# nrf7120E_enga_application register map
Vendor: Nordic Semiconductor; Series: nrf71; File version: 1
CPU: CM33 r0p4, little endian, MPU, FPU, 3 interrupt priority bits, 270 interrupts, 4 SAU regions
Registers are 32-bit, read-write, reset 0x0 unless marked. A register's access mark holds for its fields unless they carry their own. Offsets are from the block's base; [hi:lo] are bit positions; lines under a group give offsets from that group; {n}, {i} and the like mark numbered series; 'fields as' and 'values as' point back to an identical list.

## GLOBAL_USBHSCORE_NS (part 2 of 2) — USBHSCORE 0
Base 0x40020000
Same registers: GLOBAL_USBHSCORE_S 0x50020000
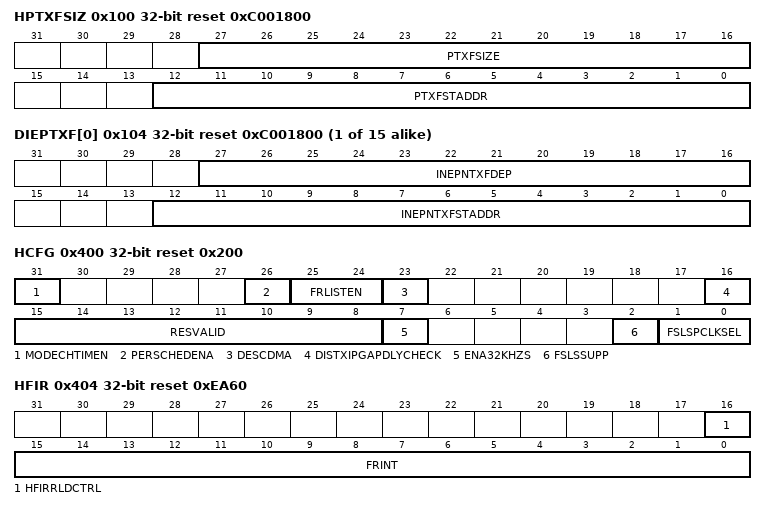
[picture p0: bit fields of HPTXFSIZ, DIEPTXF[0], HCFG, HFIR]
0x100 HPTXFSIZ reset 0xC001800 — Host Periodic Transmit FIFO Size Register
  [27:16] PTXFSIZE — Host Periodic TxFIFO Depth (PTxFSize)
  [12:0] PTXFSTADDR — Host Periodic TxFIFO Start Address (PTxFStAddr)
{0x104+4i} DIEPTXF[{i}] (i=0..14) reset 0xC001800 — Description collection: Device IN Endpoint Transmit FIFO 1 Size Register
  [27:16] INEPNTXFDEP — IN Endpoint TxFIFO Depth (INEPnTxFDep)
  [12:0] INEPNTXFSTADDR — IN Endpoint FIFOn Transmit RAM Start Address (INEPnTxFStAddr)
0x400 HCFG reset 0x200 — Host Configuration Register
  [31] MODECHTIMEN — Mode Change Ready Timer Enable (ModeChTimEn)
    0=ENABLED (The Host core waits for either 200 PHY clock cycles or a linestate of SE0 at the end of resume to change the opmode from 0x2 to 0x0); 1=DISABLED (The Host core waits only for a linestate of SE0 at the end of resume to change the opmode from 0x2 to 0x0)
  [26] PERSCHEDENA — Enable Periodic Scheduling (PerSchedEna):
    0=DISABLED (Disables periodic scheduling within the core); 1=ENABLED (Enables periodic scheduling within the core)
  [25:24] FRLISTEN — Frame List Entries(FrListEn)
    0=ENTRY8 (8 Entries); 1=ENTRY16 (16 Entries); 2=ENTRY32 (32 Entries); 3=ENTRY63 (64 Entries)
  [23] DESCDMA — Enable Scatter/gather DMA in Host mode (DescDMA)
    0=DISABLED (Scatter/Gather DMA in Host mode is disabled); 1=ENABLED (Scatter/Gather DMA selected)
  [16] DISTXIPGAPDLYCHECK — Disable Linestate check for Token to Token/Data interpacket gap delay calculation (dis_tx_ipgap_dly_check)
    0=DISABLE (Enable Linestate check); 1=ENABLE (Disable Linestate check)
  [15:8] RESVALID — Resume Validation Period (ResValid)
  [7] ENA32KHZS — Enable 32 KHz Suspend mode (Ena32KHzS)
    0=DISABLED (32 KHz Suspend mode disabled); 1=ENABLED (32 KHz Suspend mode enabled)
  [2] FSLSSUPP — FS- and LS-Only Support (FSLSSupp)
    0=HSFSLS (HS/FS/LS, based on the maximum speed supported by the connected device); 1=FSLS (FS/LS-only, even if the connected device can support HS)
  [1:0] FSLSPCLKSEL — FS/LS PHY Clock Select (FSLSPclkSel)
    0=CLK3060 (PHY clock is running at 30/60 MHz); 1=CLK48 (PHY clock is running at 48 MHz); 2=CLK6 (PHY clock is running at 6 MHz)
0x404 HFIR reset 0xEA60 — Host Frame Interval Register
  [16] HFIRRLDCTRL — Reload Control (HFIRRldCtrl)
    0=DISABLED (The HFIR cannot be reloaded dynamically); 1=ENABLED (The HFIR can be dynamically reloaded during runtime)
  [15:0] FRINT — Frame Interval (FrInt)
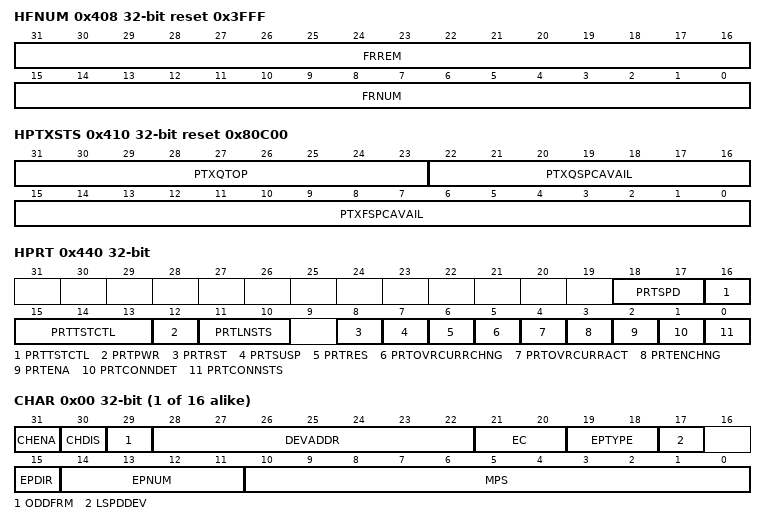
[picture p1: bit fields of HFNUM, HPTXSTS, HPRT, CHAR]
0x408 HFNUM reset 0x3FFF — Host Frame Number/Frame Time Remaining Register
  [31:16] FRREM ro — Frame Time Remaining (FrRem)
  [15:0] FRNUM ro — Frame Number (FrNum)
    0=INACTIVE (No SOF is transmitted); 1=ACTIVE (SOF is transmitted)
0x410 HPTXSTS reset 0x80C00 — Host Periodic Transmit FIFO/Queue Status Register
  [31:23] PTXQTOP ro — Top of the Periodic Transmit Request Queue (PTxQTop)
  [22:16] PTXQSPCAVAIL ro — Periodic Transmit Request Queue Space Available (PTxQSpcAvail)
    0=FULL (Periodic Transmit Request Queue is full); 1=FREE1 (1 location available); {v}=FREE{v} ({v} locations available) (v=2..15)
  [15:0] PTXFSPCAVAIL ro — Periodic Transmit Data FIFO Space Available (PTxFSpcAvail)
0x414 HAINT — Host All Channels Interrupt Register
  [15:0] HAINT ro
    0=INACTIVE (Not active); 1=ACTIVE (Host Channel Interrupt)
0x418 HAINTMSK — Host All Channels Interrupt Mask Register
  [15:0] HAINTMSK — Channel Interrupt Mask (HAINTMsk)
    0=MASK (Mask Channel interrupt); 1=UNMASK (UnMask Channel interrupt)
0x41C HFLBADDR — Host Frame List Base Address Register
  [31:0] HFLBADDR — The starting address of the Frame list.
0x440 HPRT — Host Port Control and Status Register
  [18:17] PRTSPD ro — Port Speed (PrtSpd)
    0=HIGHSPD (High speed); 1=FULLSPD (Full speed); 2=LOWSPD (Low speed)
  [16:13] PRTTSTCTL — Port Test Control (PrtTstCtl)
    0=DISABLED (Test mode disabled); 1=TESTJ (Test_J mode); 2=TESTK (Test_K mode); 3=TESTSN (Test_SE0_NAK mode); 4=TESTPM (Test_Packet mode); 5=TESTFENB (Test_force_Enable)
  [12] PRTPWR — Port Power (PrtPwr)
    0=OFF (Power off); 1=ON (Power on)
  [11:10] PRTLNSTS ro — Port Line Status (PrtLnSts)
    1=PLUSD (Logic level of D+); 2=MINUSD (Logic level of D-)
  [8] PRTRST — Port Reset (PrtRst)
    0=DISABLED (Port not in reset); 1=ENABLED (Port in reset)
  [7] PRTSUSP — Port Suspend (PrtSusp)
    0=INACTIVE (Port not in Suspend mode); 1=ACTIVE (Port in Suspend mode)
  [6] PRTRES — Port Resume (PrtRes)
    0=NORESUME (No resume driven); 1=RESUME (Resume driven)
  [5] PRTOVRCURRCHNG — Port Overcurrent Change (PrtOvrCurrChng)
    0=INACTIVE (Status of port overcurrent status is not changed); 1=ACTIVE (Status of port overcurrent changed)
  [4] PRTOVRCURRACT ro — Port Overcurrent Active (PrtOvrCurrAct)
    0=INACTIVE (No overcurrent condition); 1=ACTIVE (Overcurrent condition)
  [3] PRTENCHNG — Port Enable/Disable Change (PrtEnChng)
    0=INACTIVE (Port Enable bit 2 has not changed); 1=ACTIVE (Port Enable bit 2 changed)
  [2] PRTENA — Port Enable (PrtEna)
    0=DISABLED (Port disabled); 1=ENABLED (Port enabled)
  [1] PRTCONNDET — Port Connect Detected (PrtConnDet)
    0=INACTIVE (No device connection detected); 1=ACTIVE (Device connection detected)
  [0] PRTCONNSTS ro — Port Connect Status (PrtConnSts)
    0=NOTATTACHED (No device is attached to the port); 1=ATTACHED (A device is attached to the port)
{0x500+0x20*i} HC[{i}] (i=0..15) group — Unspecified
  0x00 CHAR — Description cluster: Host Channel Characteristics Register 0
    [31] CHENA — Channel Enable (ChEna)
      0=DISABLED (If Scatter/Gather mode is enabled, indicates that the descriptor structure is not yet ready. If Scatter/Gather mode is disabled, indicates that the channel is disabled.); 1=ENABLED (If Scatter/Gather mode is enabled, indicates that the descriptor structure and data buffer with data is set up and this channel can access the descriptor. If Scatter/Gather mode is disabled, indicates that the channel is enabled.)
    [30] CHDIS — Channel Disable (ChDis)
      0=INACTIVE (Transmit/Recieve normal); 1=ACTIVE (Stop transmitting/receiving data on channel)
    [29] ODDFRM — Odd Frame (OddFrm)
      0=EFRAME (Even Frame Transfer); 1=OFRAME (Odd Frame Transfer)
    [28:22] DEVADDR — Device Address (DevAddr)
    [21:20] EC — Multi Count (MC) / Error Count (EC)
      1=TRANSONE (1 transaction); 2=TRANSTWO (2 transactions to be issued for this endpoint per microframe); 3=TRANSTHREE (3 transactions to be issued for this endpoint per microframe)
    [19:18] EPTYPE — Endpoint Type (EPType)
      0=CTRL (Control); 1=ISOC (Isochronous); 2=BULK; 3=INTERR (Interrupt)
    [17] LSPDDEV — Low-Speed Device (LSpdDev)
      0=DISABLED (Not Communicating with low speed device); 1=ENABLED (Communicating with low speed device)
    [15] EPDIR — Endpoint Direction (EPDir)
      0=OUT (OUT Direction); 1=IN (IN Direction)
    [14:11] EPNUM — Endpoint Number (EPNum)
      {v}=ENDPT{v} (End point {v}) (v=0..15)
    [10:0] MPS — Maximum Packet Size (MPS)
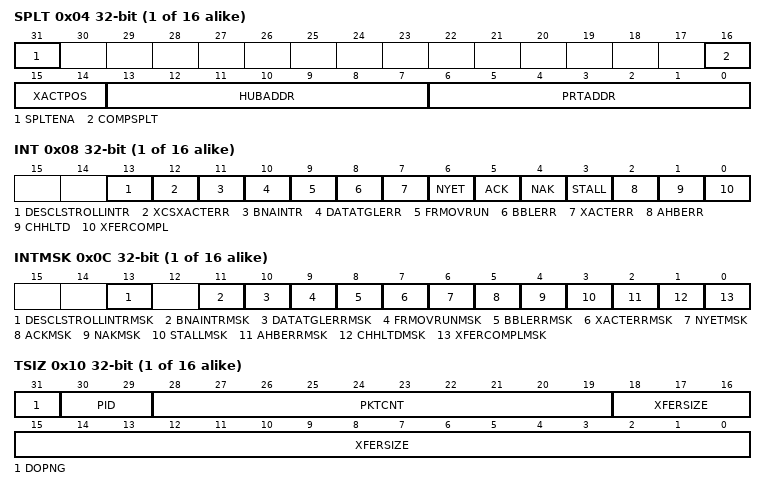
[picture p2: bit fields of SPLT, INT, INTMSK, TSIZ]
  0x04 SPLT — Description cluster: Host Channel Split Control Register 0
    [31] SPLTENA — Split Enable (SpltEna)
      0=DISABLED (Split not enabled); 1=ENABLED (Split enabled)
    [16] COMPSPLT — Do Complete Split (CompSplt)
      0=NOSPLIT (No complete split transaction); 1=SPLIT (Complete Split transaction)
    [15:14] XACTPOS — Transaction Position (XactPos)
      0=MIDDLE (Mid. This is the middle payload of this transaction (which is larger than 188 bytes)); 1=END (End. This is the last payload of this transaction (which is larger than 188 bytes)); 2=BEGIN (Begin. This is the first data payload of this transaction (which is larger than 188 bytes)); 3=ALL (All. This is the entire data payload of this transaction (which is less than or equal to 188 bytes))
    [13:7] HUBADDR — Hub Address (HubAddr)
    [6:0] PRTADDR — Port Address (PrtAddr)
  0x08 INT — Description cluster: Host Channel Interrupt Register 0
    [13] DESCLSTROLLINTR — Descriptor rollover interrupt (DESC_LST_ROLLIntr)
      0=INACTIVE (No Descriptor rollover interrupt); 1=ACTIVE (Descriptor rollover interrupt)
    [12] XCSXACTERR — Excessive Transaction Error (XCS_XACT_ERR)
      0=INACTIVE (No Excessive Transaction Error); 1=ACTIVE (Excessive Transaction Error)
    [11] BNAINTR — BNA (Buffer Not Available) Interrupt (BNAIntr)
      0=INACTIVE (No BNA Interrupt); 1=ACTIVE (BNA Interrupt)
    [10] DATATGLERR
      0=INACTIVE (No Data Toggle Error); 1=ACTIVE (Data Toggle Error)
    [9] FRMOVRUN — Frame Overrun (FrmOvrun).
      0=INACTIVE (No Frame Overrun); 1=ACTIVE (Frame Overrun)
    [8] BBLERR — Babble Error (BblErr)
      0=INACTIVE (No Babble Error); 1=ACTIVE (Babble Error)
    [7] XACTERR — Transaction Error (XactErr)
      0=INACTIVE (No Transaction Error); 1=ACTIVE (Transaction Error)
    [6] NYET — NYET Response Received Interrupt (NYET)
      0=INACTIVE (No NYET Response Received Interrupt); 1=ACTIVE (NYET Response Received Interrupt)
    [5] ACK — ACK Response Received/Transmitted Interrupt (ACK)
      0=INACTIVE (No ACK Response Received or Transmitted Interrupt); 1=ACTIVE (ACK Response Received or Transmitted Interrup)
    [4] NAK — NAK Response Received Interrupt (NAK)
      0=INACTIVE (No NAK Response Received Interrupt); 1=ACTIVE (NAK Response Received Interrupt)
    [3] STALL — STALL Response Received Interrupt (STALL)
      0=INACTIVE (No Stall Response Received Interrupt); 1=ACTIVE (Stall Response Received Interrupt)
    [2] AHBERR — AHB Error (AHBErr)
      0=INACTIVE (No AHB error); 1=ACTIVE (AHB error during AHB read/write)
    [1] CHHLTD — Channel Halted (ChHltd)
      0=INACTIVE (Channel not halted); 1=ACTIVE (Channel Halted)
    [0] XFERCOMPL — Transfer Completed (XferCompl)
      0=INACTIVE (Transfer in progress or No Active Transfer); 1=ACTIVE (Transfer completed normally without any errors)
  0x0C INTMSK — Description cluster: Host Channel Interrupt Mask Register 0
    [13] DESCLSTROLLINTRMSK
      0=MASK (Descriptor Rollover Interrupt Mask); 1=NOMASK (Descriptor Rollover Interrupt not masked)
    [11] BNAINTRMSK
      0=MASK (BNA Interrupt Masked); 1=NOMASK (BNA Interrupt not masked)
    [10] DATATGLERRMSK
      0=MASK (Mask Data Toggle Error); 1=NOMASK (No Data Toggle Error Mask)
    [9] FRMOVRUNMSK
      0=MASK (Mask Overrun Mask); 1=NOMASK (No Frame Overrun Mask)
    [8] BBLERRMSK
      0=MASK (Mask Babble Error); 1=NOMASK (No Babble Error Mask)
    [7] XACTERRMSK
      0=MASK (Mask Transaction Error); 1=NOMASK (No Transaction Error Mask)
    [6] NYETMSK
      0=MASK (Mask NYET Response Received Interrupt); 1=NOMASK (No NYET Response Received Interrupt Mask)
    [5] ACKMSK
      0=MASK (Mask ACK Response Received/Transmitted Interrupt); 1=NOMASK (No ACK Response Received/Transmitted Interrupt Mask)
    [4] NAKMSK
      0=MASK (Mask NAK Response Received Interrupt); 1=NOMASK (No NAK Response Received Interrupt Mask)
    [3] STALLMSK
      0=MASK (Mask STALL Response Received Interrupt); 1=NOMASK (No STALL Response Received Interrupt Mask)
    [2] AHBERRMSK
      0=MASK (AHB Error Mask); 1=NOMASK (No AHB Error Mask)
    [1] CHHLTDMSK
      0=MASK (Channel Halted Mask); 1=NOMASK (No Channel Halted Mask)
    [0] XFERCOMPLMSK
      0=MASK (Transfer Completed Mask); 1=NOMASK (No Transfer Completed Mask)
  0x10 TSIZ — Description cluster: Host Channel Transfer Size Register 0
    [31] DOPNG — Do Ping (DoPng)
      0=NOPING (No ping protocol); 1=PING (Ping protocol)
    [30:29] PID — PID (Pid)
      0=DATA0; 1=DATA2; 2=DATA1; 3=MDATA (MDATA (non-control)/SETUP (control))
    [28:19] PKTCNT — Non-Scatter/Gather DMA Mode:
    [18:0] XFERSIZE — Non-Scatter/Gather DMA Mode:
  0x14 DMA — Description cluster: Host Channel DMA Address Register 0
    [31:0] DMAADDR — In Buffer DMA Mode:
  0x1C DMAB — Description cluster: Host Channel DMA Buffer Address Register 0
    [31:0] HCDMAB ro — Holds the current buffer address.
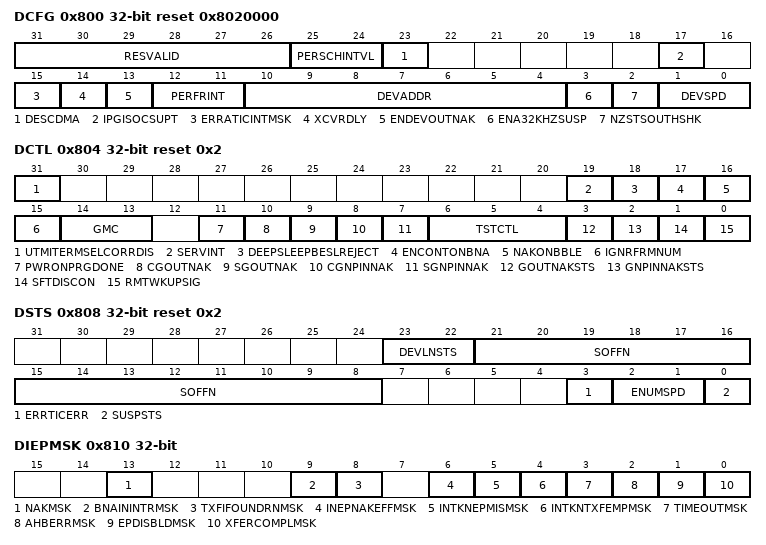
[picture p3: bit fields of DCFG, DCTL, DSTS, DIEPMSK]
0x800 DCFG reset 0x8020000 — Device Configuration Register
  [31:26] RESVALID — Resume Validation Period (ResValid)
  [25:24] PERSCHINTVL — Periodic Scheduling Interval (PerSchIntvl)
    0=MF25 (25 percent of (micro)Frame); 1=MF50 (50 percent of (micro)Frame); 2=MF75 (75 percent of (micro)Frame)
  [23] DESCDMA — Enable Scatter/gather DMA in device mode (DescDMA).
    0=DISABLED (Disable Scatter/Gather DMA); 1=ENABLED (Enable Scatter/Gather DMA)
  [17] IPGISOCSUPT — Worst-Case Inter-Packet Gap ISOC OUT Support (ipgisocSupt)
    0=DISABLED (Worst-Case Inter-Packet Gap ISOC OUT Support is disabled); 1=ENABLED (Worst-Case Inter-Packet Gap ISOC OUT Support is enabled)
  [15] ERRATICINTMSK — Erratic Error Interrupt Mask
    0=NOMASK (Early suspend interrupt is generated on erratic error); 1=MASK (Mask early suspend interrupt on erratic error)
  [14] XCVRDLY
    0=DISABLE (No delay between xcvr_sel and txvalid during Device chirp); 1=ENABLE (Enable delay between xcvr_sel and txvalid during Device chirp)
  [13] ENDEVOUTNAK — Enable Device OUT NAK (EnDevOutNak)
    0=DISABLED (The core does not set NAK after Bulk OUT transfer complete); 1=ENABLED (The core sets NAK after Bulk OUT transfer complete)
  [12:11] PERFRINT — Periodic Frame Interval (PerFrInt)
    0=EOPF80 (80 percent of the (micro)Frame interval); 1=EOPF85 (85 percent of the (micro)Frame interval); 2=EOPF90 (90 percent of the (micro)Frame interval); 3=EOPF95 (95 percent of the (micro)Frame interval)
  [10:4] DEVADDR — Device Address (DevAddr)
  [3] ENA32KHZSUSP — Enable 32 KHz Suspend mode (Ena32KHzSusp)
    0=DISABLED (USB 1.1 Full-Speed Serial Transceiver not selected); 1=ENABLED (USB 1.1 Full-Speed Serial Transceiver Interface selected)
  [2] NZSTSOUTHSHK — Non-Zero-Length Status OUT Handshake (NZStsOUTHShk)
    0=SENDOUT (Send the received OUT packet to the application (zero-length or non-zero length) and send a handshake based on NAK and STALL bits for the endpoint in the Devce Endpoint Control Register); 1=SENDSTALL (Send a STALL handshake on a nonzero-length status OUT transaction and do not send the received OUT packet to the application)
  [1:0] DEVSPD — Device Speed (DevSpd)
    0=USBHS20 (High speed USB 2.0 PHY clock is 30 MHz or 60 MHz); 1=USBFS20 (Full speed USB 2.0 PHY clock is 30 MHz or 60 MHz); 2=USBLS116 (Low speed USB 1.1 transceiver clock is 6 MHz); 3=USBFS1148 (Full speed USB 1.1 transceiver clock is 48 MHz)
0x804 DCTL reset 0x2 — Device Control Register
  [31] UTMITERMSELCORRDIS — Disable the correction of TermSel on UTMI Interface.
    0=DISABLED (Valid Combination of XcvrSel and TermSel is driven by the Device Controller.); 1=ENABLED (Invalid Combination of XcvrSel and TermSel is driven by the Device Controller.)
  [19] SERVINT — Service Interval based scheduling for Isochronous IN Endpoints
    0=DISABLED (The controller behavior depends on DCTL.IgnrFrmNum field.); 1=ENABLED (Scatter/Gather DMA Mode: The controller can transmit the packets in any frame of the service interval.)
  [18] DEEPSLEEPBESLREJECT
    0=DISABLED (Deep Sleep BESL Reject feature is disabled); 1=ENABLED (Deep Sleep BESL Reject feature is enabled)
  [17] ENCONTONBNA — Enable Continue on BNA (EnContOnBNA)
    0=DISABLED (Core disables the endpoint after receiving BNA interrupt. When application re-enables the endpoint, core starts processing from the DOEPDMA descriptor); 1=ENABLED (Core disables the endpoint after receiving BNA interrupt. When application re-enables the endpoint, core starts processing from the descriptor that received the BNA interrupt.)
  [16] NAKONBBLE — NAK on Babble Error (NakOnBble)
    0=DISABLED (Disable NAK on Babble Error); 1=ENABLED (NAK on Babble Error)
  [15] IGNRFRMNUM — Ignore Frame Number Feature for Isochronous Endpoints (IgnrFrmNum)
    0=DISABLED (Scatter/Gather DMA Mode: The core transmits the packets only in the frame number in which they are intended to be transmitted.Non-Scatter/Gather DMA Mode: Periodic Transfer Interrupt feature is disabled.); 1=ENABLED (Scatter/Gather DMA Mode: The core ignores the frame number, sending packets immediately as the packets are ready.Non-Scatter/Gather DMA Mode: Periodic Transfer Interrupt feature is enabled.)
  [14:13] GMC — Global Multi Count (GMC)
    0=NOTVALID (Invalid); 1=ONEPACKET (1 packet); 2=TWOPACKET (2 packets); 3=THREEPACKET (3 packets)
  [11] PWRONPRGDONE — Power-On Programming Done (PWROnPrgDone)
    0=NOTDONE (Power-On Programming not done); 1=DONE (Power-On Programming Done)
  [10] CGOUTNAK wo — Clear Global OUT NAK (CGOUTNak)
    0=DISABLED (Disable Clear Global OUT NAK); 1=ENABLED (Clear Global OUT NAK)
  [9] SGOUTNAK wo — Set Global OUT NAK (SGOUTNak)
    0=DISABLED (Disable Global OUT NAK); 1=ENABLED (Set Global OUT NAK)
  [8] CGNPINNAK wo — Clear Global Non-periodic IN NAK (CGNPInNak)
    0=DISABLE (Disable Global Non-periodic IN NAK); 1=ENABLE (Clear Global Non-periodic IN NAK)
  [7] SGNPINNAK wo — Set Global Non-periodic IN NAK (SGNPInNak)
    0=DISABLE (Disable Global Non-periodic IN NAK); 1=ENABLE (Set Global Non-periodic IN NAK)
  [6:4] TSTCTL — Test Control (TstCtl)
    0=DISABLED (Test mode disabled); 1=TESTJ (Test_J mode); 2=TESTK (Test_K mode); 3=TESTSN (Test_SE0_NAK mode); 4=TESTPM (Test_Packet mode); 5=TESTFE (Test_force_Enable)
  [3] GOUTNAKSTS ro — Global OUT NAK Status (GOUTNakSts)
    0=INACTIVE (A handshake is sent based on the FIFO Status and the NAK and STALL bit settings.); 1=ACTIVE (No data is written to the RxFIFO, irrespective of space availability. Sends a NAK handshake on all packets, except on SETUP transactions. All isochronous OUT packets are dropped.)
  [2] GNPINNAKSTS ro — Global Non-periodic IN NAK Status (GNPINNakSts)
    0=INACTIVE (A handshake is sent out based on the data availability in the transmit FIFO); 1=ACTIVE (A NAK handshake is sent out on all non-periodic IN endpoints, irrespective of the data availability in the transmit FIFO.)
  [1] SFTDISCON — Soft Disconnect (SftDiscon)
    0=NODISCONNECT (The core drives the phy_opmode_o signal on the UTMI+ to 2'b00, which generates a device connect event to the USB host); 1=DISCONNECT (The core drives the phy_opmode_o signal on the UTMI+ to 2'b01, which generates a device disconnect event to the USB host)
  [0] RMTWKUPSIG — Remote Wakeup Signaling (RmtWkUpSig)
    0=DISABLEDRMWKUP (Core does not send Remote Wakeup Signaling); 1=ENABLERMWKUP (Core sends Remote Wakeup Signaling)
0x808 DSTS reset 0x2 — Device Status Register
  [23:22] DEVLNSTS ro — Device Line Status (DevLnSts)
  [21:8] SOFFN ro — Frame or Microframe Number of the Received SOF (SOFFN)
  [3] ERRTICERR ro — Erratic Error (ErrticErr)
    0=INACTIVE (No Erratic Error); 1=ACTIVE (Erratic Error)
  [2:1] ENUMSPD ro — Enumerated Speed (EnumSpd)
    0=HS3060 (High speed (PHY clock is running at 30 or 60 MHz)); 1=FS3060 (Full speed (PHY clock is running at 30 or 60 MHz)); 2=LS6 (Low speed (PHY clock is running at 6 MHz)); 3=FS48 (Full speed (PHY clock is running at 48 MHz))
  [0] SUSPSTS ro — Suspend Status (SuspSts)
    0=INACTIVE (No suspend state); 1=ACTIVE (Suspend state)
0x810 DIEPMSK — Device IN Endpoint Common Interrupt Mask Register
  [13] NAKMSK — NAK interrupt Mask (NAKMsk)
    0=MASK (Mask NAK Interrupt); 1=NOMASK (No Mask NAK Interrupt)
  [9] BNAININTRMSK — BNA interrupt Mask (BNAInIntrMsk)
    0=MASK (Mask BNA Interrupt); 1=NOMASK (No BNA Interrupt Mask)
  [8] TXFIFOUNDRNMSK — Fifo Underrun Mask (TxfifoUndrnMsk)
    0=MASK (Mask Fifo Underrun Interrupt); 1=NOMASK (No Fifo Underrun Interrupt Mask)
  [6] INEPNAKEFFMSK — IN Endpoint NAK Effective Mask (INEPNakEffMsk)
    0=MASK (Mask IN Endpoint NAK Effective Interrupt); 1=NOMASK (No IN Endpoint NAK Effective Interrupt Mask)
  [5] INTKNEPMISMSK — IN Token received with EP Mismatch Mask (INTknEPMisMsk)
    0=MASK (Mask IN Token received with EP Mismatch Interrupt); 1=NOMASK (No Mask IN Token received with EP Mismatch Interrupt)
  [4] INTKNTXFEMPMSK — IN Token Received When TxFIFO Empty Mask (INTknTXFEmpMsk)
    0=MASK (Mask IN Token Received When TxFIFO Empty Interrupt); 1=NOMASK (No IN Token Received When TxFIFO Empty Interrupt)
  [3] TIMEOUTMSK — Timeout Condition Mask (TimeOUTMsk) (Non-isochronous endpoints)
    0=MASK (Mask Timeout Condition Interrupt); 1=NOMASK (No Timeout Condition Interrupt Mask)
  [2] AHBERRMSK — AHB Error Mask (AHBErrMsk)
    0=MASK (Mask AHB Error Interrupt); 1=NOMASK (No AHB Error Interrupt Mask)
  [1] EPDISBLDMSK — Endpoint Disabled Interrupt Mask (EPDisbldMsk)
    0=MASK (Mask Endpoint Disabled Interrupt); 1=NOMASK (No Endpoint Disabled Interrupt Mask)
  [0] XFERCOMPLMSK — Transfer Completed Interrupt Mask (XferComplMsk)
    0=MASK (Mask Transfer Completed Interrupt); 1=NOMASK (No Transfer Completed Interrupt Mask)
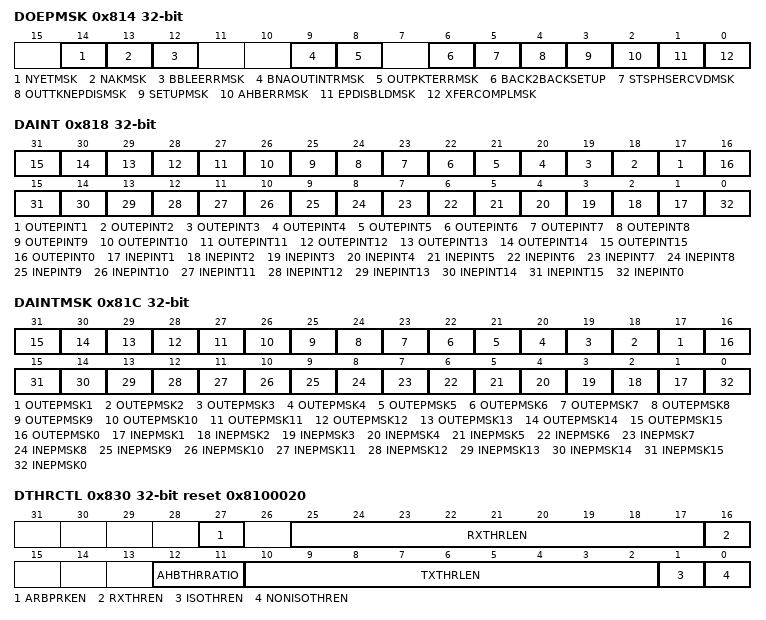
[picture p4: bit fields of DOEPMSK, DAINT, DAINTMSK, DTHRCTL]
0x814 DOEPMSK — Device OUT Endpoint Common Interrupt Mask Register
  [14] NYETMSK — NYET interrupt Mask (NYETMsk)
    0=MASK (Mask NYET Interrupt); 1=NOMASK (No NYET Interrupt Mask)
  [13] NAKMSK — NAK interrupt Mask (NAKMsk)
    0=MASK (Mask NAK Interrupt); 1=NOMASK (No NAK Interrupt Mask)
  [12] BBLEERRMSK — Babble Error interrupt Mask (BbleErrMsk)
    0=MASK (Mask Babble Error Interrupt); 1=NOMASK (No Babble Error Interrupt Mask)
  [9] BNAOUTINTRMSK — BNA interrupt Mask (BnaOutIntrMsk)
    values as DIEPMSK.BNAININTRMSK
  [8] OUTPKTERRMSK — OUT Packet Error Mask (OutPktErrMsk)
    0=MASK (Mask OUT Packet Error Interrupt); 1=NOMASK (No OUT Packet Error Interrupt Mask)
  [6] BACK2BACKSETUP — Back-to-Back SETUP Packets Received Mask (Back2BackSETup)
    0=MASK (Mask Back-to-Back SETUP Packets Received Interrupt); 1=NOMASK (No Back-to-Back SETUP Packets Received Interrupt Mask)
  [5] STSPHSERCVDMSK — Status Phase Received Mask (StsPhseRcvdMsk)
    0=MASK (Status Phase Received Mask); 1=NOMASK (No Status Phase Received Mask)
  [4] OUTTKNEPDISMSK — OUT Token Received when Endpoint Disabled Mask (OUTTknEPdisMsk)
    0=MASK (Mask OUT Token Received when Endpoint Disabled Interrupt); 1=NOMASK (No OUT Token Received when Endpoint Disabled Interrupt Mask)
  [3] SETUPMSK — SETUP Phase Done Mask (SetUPMsk)
    0=MASK (Mask SETUP Phase Done Interrupt); 1=NOMASK (No SETUP Phase Done Interrupt Mask)
  [2] AHBERRMSK — AHB Error (AHBErrMsk)
    values as DIEPMSK.AHBERRMSK
  [1] EPDISBLDMSK — Endpoint Disabled Interrupt Mask (EPDisbldMsk)
    values as DIEPMSK.EPDISBLDMSK
  [0] XFERCOMPLMSK — Transfer Completed Interrupt Mask (XferComplMsk)
    values as DIEPMSK.XFERCOMPLMSK
0x818 DAINT — Device All Endpoints Interrupt Register
  [n+16] OUTEPINT{n} ro (n=1..15) — OUT Endpoint {n} Interrupt Bit
    0=INACTIVE (No Interrupt); 1=ACTIVE (Interrupt is active for the OUT EP)
  [16] OUTEPINT0 ro — OUT Endpoint 0 Interrupt Bit
    0=INACTIVE (No Interrupt); 1=ACTIVE (Interrupt is active for OUT EP0)
  [n] INEPINT{n} ro (n=1..15) — IN Endpoint {n} Interrupt Bit
    0=INACTIVE (No Interrupt); 1=ACTIVE (Interrupt is active for the IN EP)
  [0] INEPINT0 ro — IN Endpoint 0 Interrupt Bit
    0=INACTIVE (No Interrupt); 1=ACTIVE (Interrupt is active for IN EP0)
0x81C DAINTMSK — Device All Endpoints Interrupt Mask Register
  [n+16] OUTEPMSK{n} (n=1..15) — OUT Endpoint {n} Interrupt mask Bit
    0=MASK (Mask OUT Endpoint Interrupt); 1=NOMASK (No Interrupt mask)
  [16] OUTEPMSK0 — OUT Endpoint 0 Interrupt mask Bit
    0=MASK (Mask OUT Endpoint 0 Interrupt); 1=NOMASK (No Interrupt mask)
  [n] INEPMSK{n} (n=1..15) — IN Endpoint {n} Interrupt mask Bit
    0=MASK (Mask IN Endpoint Interrupt); 1=NOMASK (No Interrupt mask)
  [0] INEPMSK0 — IN Endpoint 0 Interrupt mask Bit
    0=MASK (Mask IN Endpoint 0 Interrupt); 1=NOMASK (No Interrupt mask)
0x828 DVBUSDIS reset 0x17D7 — Device VBUS Discharge Time Register
  [15:0] DVBUSDIS — Device VBUS Discharge Time (DVBUSDis)
0x82C DVBUSPULSE reset 0x5B8 — Device VBUS Pulsing Time Register
  [11:0] DVBUSPULSE — Device VBUS Pulsing Time (DVBUSPulse)
0x830 DTHRCTL reset 0x8100020 — Device Threshold Control Register
  [27] ARBPRKEN — Arbiter Parking Enable (ArbPrkEn)
    0=DISABLED (Disable DMA arbiter parking); 1=ENABLED (Enable DMA arbiter parking for IN endpoints)
  [25:17] RXTHRLEN — Receive Threshold Length (RxThrLen)
  [16] RXTHREN — Receive Threshold Enable (RxThrEn)
    0=DISABLED (Disable thresholding); 1=ENABLED (Enable thresholding in the receive direction)
  [12:11] AHBTHRRATIO — AHB Threshold Ratio (AHBThrRatio)
    0=THRESZERO (AHB threshold = MAC threshold); 1=THRESONE (AHB threshold = MAC threshold /2); 2=THRESTWO (AHB threshold = MAC threshold /4); 3=THRESTHREE (AHB threshold = MAC threshold /8)
  [10:2] TXTHRLEN — Transmit Threshold Length (TxThrLen)
  [1] ISOTHREN
    0=DISABLED (No thresholding); 1=ENABLED (Enables thresholding for isochronous IN endpoints)
  [0] NONISOTHREN — Non-ISO IN Endpoints Threshold Enable. (NonISOThrEn)
    0=DISABLED (No thresholding); 1=ENABLED (Enable thresholding for non-isochronous IN endpoints)
0x834 DIEPEMPMSK — Device IN Endpoint FIFO Empty Interrupt Mask Register
  [15:0] INEPTXFEMPMSK — IN EP Tx FIFO Empty Interrupt Mask Bits (InEpTxfEmpMsk)
    1=EP0_MASK (Mask IN EP0 Tx FIFO Empty Interrupt); 2=EP1_MASK (Mask IN EP1 Tx FIFO Empty Interrupt); 4=EP2_MASK (Mask IN EP2 Tx FIFO Empty Interrupt); 8=EP3_MASK (Mask IN EP3 Tx FIFO Empty Interrupt); 16=EP4_MASK (Mask IN EP4 Tx FIFO Empty Interrupt); 32=EP5_MASK (Mask IN EP5 Tx FIFO Empty Interrupt); 64=EP6_MASK (Mask IN EP6 Tx FIFO Empty Interrupt); 128=EP7_MASK (Mask IN EP7 Tx FIFO Empty Interrupt); 0x100=EP8_MASK (Mask IN EP8 Tx FIFO Empty Interrupt); 0x200=EP9_MASK (Mask IN EP9 Tx FIFO Empty Interrupt); 0x400=EP10_MASK (Mask IN EP10 Tx FIFO Empty Interrupt); 0x800=EP11_MASK (Mask IN EP11 Tx FIFO Empty Interrupt); 0x1000=EP12_MASK (Mask IN EP12 Tx FIFO Empty Interrupt); 0x2000=EP13_MASK (Mask IN EP13 Tx FIFO Empty Interrupt); 0x4000=EP14_MASK (Mask IN EP14 Tx FIFO Empty Interrupt); 0x8000=EP15_MASK (Mask IN EP15 Tx FIFO Empty Interrupt)
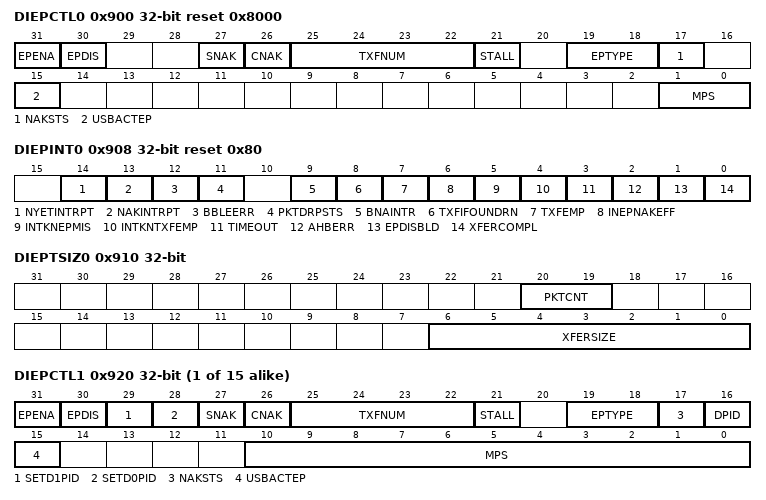
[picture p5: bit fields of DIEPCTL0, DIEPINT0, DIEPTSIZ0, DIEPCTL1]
0x900 DIEPCTL0 reset 0x8000 — Device Control IN Endpoint 0 Control Register
  [31] EPENA — Endpoint Enable (EPEna)
    0=INACTIVE (No action); 1=ACTIVE (Enable Endpoint)
  [30] EPDIS — Endpoint Disable (EPDis)
    0=INACTIVE (No action); 1=ACTIVE (Disabled Endpoint)
  [27] SNAK wo
    0=NOSET (No action); 1=SET (Set NAK)
  [26] CNAK wo
    0=NOCLEAR (No action); 1=CLEAR (Clear NAK)
  [25:22] TXFNUM — TxFIFO Number (TxFNum)
    {v}=TXFIFO{v} (v=0..15)
  [21] STALL — STALL Handshake (Stall)
    0=INACTIVE (No Stall); 1=ACTIVE (Stall Handshake)
  [19:18] EPTYPE ro — Endpoint Type (EPType)
    0=ACTIVE (Endpoint Control 0)
  [17] NAKSTS ro — NAK Status (NAKSts)
    0=INACTIVE (The core is transmitting non-NAK handshakes based on the FIFO status); 1=ACTIVE (The core is transmitting NAK handshakes on this endpoint)
  [15] USBACTEP ro — USB Active Endpoint (USBActEP)
    1=ACTIVE0 (Control endpoint is always active)
  [1:0] MPS — Maximum Packet Size (MPS)
    0=BYTES64 (64 bytes); 1=BYTES32 (32 bytes); 2=BYTES16 (16 bytes); 3=BYTES8 (8 bytes)
0x908 DIEPINT0 reset 0x80 — Device IN Endpoint 0 Interrupt Register
  [14] NYETINTRPT — NYET Interrupt (NYETIntrpt)
    0=INACTIVE (No interrupt); 1=ACTIVE (NYET Interrupt)
  [13] NAKINTRPT — NAK Interrupt (NAKInterrupt)
    0=INACTIVE (No interrupt); 1=ACTIVE (NAK Interrupt)
  [12] BBLEERR — NAK Interrupt (BbleErr)
    0=INACTIVE (No interrupt); 1=ACTIVE (BbleErr interrupt)
  [11] PKTDRPSTS — Packet Drop Status (PktDrpSts)
    0=INACTIVE (No interrupt); 1=ACTIVE (Packet Drop Status)
  [9] BNAINTR — BNA (Buffer Not Available) Interrupt (BNAIntr)
    0=INACTIVE (No BNA interrupt); 1=ACTIVE (BNA interrupt)
  [8] TXFIFOUNDRN — Fifo Underrun (TxfifoUndrn)
    0=INACTIVE (No Fifo Underrun interrupt); 1=ACTIVE (Fifo Underrun interrupt)
  [7] TXFEMP ro — Transmit FIFO Empty (TxFEmp)
    0=INACTIVE (No Transmit FIFO Empty interrupt); 1=ACTIVE (Transmit FIFO Empty interrupt)
  [6] INEPNAKEFF — IN Endpoint NAK Effective (INEPNakEff)
    0=INACTIVE (No IN Endpoint NAK Effective interrupt); 1=ACTIVE (IN Endpoint NAK Effective interrupt)
  [5] INTKNEPMIS — IN Token Received with EP Mismatch (INTknEPMis)
    0=INACTIVE (No IN Token Received with EP Mismatch interrupt); 1=ACTIVE (IN Token Received with EP Mismatch interrupt)
  [4] INTKNTXFEMP — IN Token Received When TxFIFO is Empty (INTknTXFEmp)
    0=INACTIVE (No IN Token Received when TxFIFO Empty interrupt); 1=ACTIVE (IN Token Received when TxFIFO Empty Interrupt)
  [3] TIMEOUT — Timeout Condition (TimeOUT)
    0=INACTIVE (No Timeout interrupt); 1=ACTIVE (Timeout interrupt)
  [2] AHBERR — AHB Error (AHBErr)
    0=INACTIVE (No AHB Error Interrupt); 1=ACTIVE (AHB Error interrupt)
  [1] EPDISBLD — Endpoint Disabled Interrupt (EPDisbld)
    0=INACTIVE (No Endpoint Disabled Interrupt); 1=ACTIVE (Endpoint Disabled Interrupt)
  [0] XFERCOMPL — Transfer Completed Interrupt (XferCompl)
    0=INACTIVE (No Transfer Complete Interrupt); 1=ACTIVE (Transfer Completed Interrupt)
0x910 DIEPTSIZ0 — Device IN Endpoint 0 Transfer Size Register
  [20:19] PKTCNT — Packet Count (PktCnt)
  [6:0] XFERSIZE — Transfer Size (XferSize)
0x914 DIEPDMA0 — Device IN Endpoint 0 DMA Address Register
  [31:0] DMAADDR
{0x918+0x20*i} DTXFSTS{i} reset 0xC00 (i=0..15) — Device IN Endpoint Transmit FIFO Status Register {i}
  [15:0] INEPTXFSPCAVAIL ro — IN Endpoint TxFIFO Space Avail (INEPTxFSpcAvail)
0x91C DIEPDMAB0 — Device IN Endpoint 0 Buffer Address Register
  [31:0] DMABUFFERADDR ro — Holds the current buffer address.This register is updated as and when the data
{0x900+0x20*i} DIEPCTL{i} (i=1..15) — Device Control IN Endpoint Control Register {i}
  [31] EPENA — Endpoint Enable (EPEna)
    0=INACTIVE (No Action); 1=ACTIVE (Enable Endpoint)
  [30] EPDIS — Endpoint Disable (EPDis)
    0=INACTIVE (No Action); 1=ACTIVE (Disable Endpoint)
  [29] SETD1PID wo — Set DATA1 PID (SetD1PID)
    0=DISABLED (Disables Set DATA1 PID or Do not force Odd (micro)Frame); 1=ENABLED (Set Endpoint Data PID to DATA1 or Sets EO_FrNum field to Odd (micro)Frame)
  [28] SETD0PID wo — Set DATA0 PID (SetD0PID)
    0=DISABLED (Disables Set DATA0 PID or Do not force Even (micro)Frame); 1=ENABLED (Set Endpoint Data PID to DATA0 or Sets EO_FrNum field to Even (micro)Frame)
  [27] SNAK wo — Set NAK (SNAK)
    0=INACTIVE (No Set NAK); 1=ACTIVE (Set NAK)
  [26] CNAK wo — Clear NAK (CNAK)
    0=INACTIVE (No Clear NAK); 1=ACTIVE (Clear NAK)
  [25:22] TXFNUM — TxFIFO Number (TxFNum)
    {v}=TXFIFO{v} (v=0..15)
  [21] STALL — STALL Handshake (Stall)
    0=INACTIVE (STALL All non-active tokens); 1=ACTIVE (STALL All Active Tokens)
  [19:18] EPTYPE — Endpoint Type (EPType)
    0=CONTROL; 1=ISOCHRONOUS; 2=BULK; 3=INTERRUP (Interrupt)
  [17] NAKSTS ro — NAK Status (NAKSts)
    0=NONNAK (The core is transmitting non-NAK handshakes based on the FIFO status); 1=NAK (The core is transmitting NAK handshakes on this endpoint)
  [16] DPID ro
    0=DATA0EVENFRM (DATA0 or Even Frame); 1=DATA1ODDFRM (DATA1 or Odd Frame)
  [15] USBACTEP — USB Active Endpoint (USBActEP)
    0=DISABLED (Not Active); 1=ENABLED (USB Active Endpoint)
  [10:0] MPS — Maximum Packet Size (MPS)
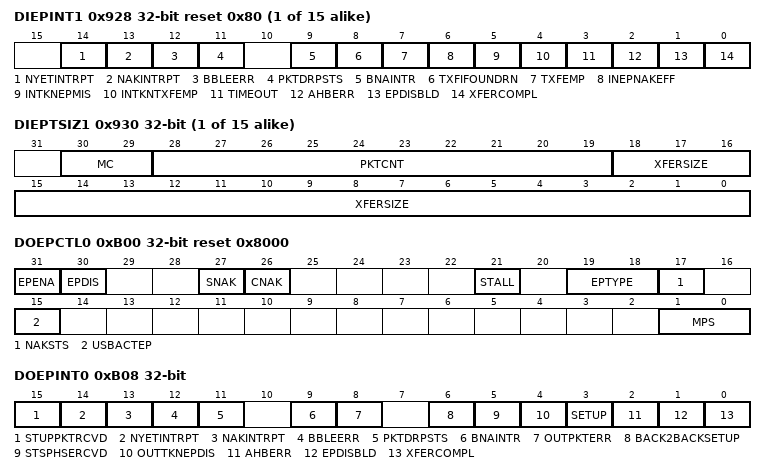
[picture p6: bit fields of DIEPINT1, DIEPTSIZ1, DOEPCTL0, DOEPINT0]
{0x908+0x20*i} DIEPINT{i} reset 0x80 (i=1..15) — Device IN Endpoint Interrupt Register {i}
  [14] NYETINTRPT — NYET Interrupt (NYETIntrpt)
    0=INACTIVE (No NYET interrupt); 1=ACTIVE (NYET Interrupt)
  [13] NAKINTRPT — NAK Interrupt (NAKInterrupt)
    0=INACTIVE (No NAK interrupt); 1=ACTIVE (NAK Interrupt)
  [12] BBLEERR — NAK Interrupt (BbleErr)
    0=INACTIVE (No interrupt); 1=ACTIVE (BbleErr interrupt)
  [11] PKTDRPSTS — Packet Drop Status (PktDrpSts)
    0=INACTIVE (No interrupt); 1=ACTIVE (Packet Drop Status interrupt)
  [9] BNAINTR — BNA (Buffer Not Available) Interrupt (BNAIntr)
    0=INACTIVE (No BNA interrupt); 1=ACTIVE (BNA interrupt)
  [8] TXFIFOUNDRN — Fifo Underrun (TxfifoUndrn)
    0=INACTIVE (No Tx FIFO Underrun interrupt); 1=ACTIVE (TxFIFO Underrun interrupt)
  [7] TXFEMP ro — Transmit FIFO Empty (TxFEmp)
    values as DIEPINT0.TXFEMP
  [6] INEPNAKEFF — IN Endpoint NAK Effective (INEPNakEff)
    0=INACTIVE (No Endpoint NAK Effective interrupt); 1=ACTIVE (IN Endpoint NAK Effective interrupt)
  [5] INTKNEPMIS — IN Token Received with EP Mismatch (INTknEPMis)
    values as DIEPINT0.INTKNEPMIS
  [4] INTKNTXFEMP — IN Token Received When TxFIFO is Empty (INTknTXFEmp)
    0=INACTIVE (No IN Token Received interrupt); 1=ACTIVE (IN Token Received Interrupt)
  [3] TIMEOUT — Timeout Condition (TimeOUT)
    values as DIEPINT0.TIMEOUT
  [2] AHBERR — AHB Error (AHBErr)
    values as DIEPINT0.AHBERR
  [1] EPDISBLD — Endpoint Disabled Interrupt (EPDisbld)
    values as DIEPINT0.EPDISBLD
  [0] XFERCOMPL — Transfer Completed Interrupt (XferCompl)
    0=INACTIVE (No Transfer Complete Interrupt); 1=ACTIVE (Transfer Complete Interrupt)
{0x910+0x20*i} DIEPTSIZ{i} (i=1..15) — Device IN Endpoint Transfer Size Register {i}
  [30:29] MC
    1=PACKETONE (1 packet); 2=PACKETTWO (2 packets); 3=PACKETTHREE (3 packets)
  [28:19] PKTCNT — Packet Count (PktCnt)
  [18:0] XFERSIZE — Transfer Size (XferSize)
{0x914+0x20*i} DIEPDMA{i} (i=1..15) — Device IN Endpoint DMA Address Register {i}
  [31:0] DMAADDR — Holds the start address of the external memory for storing or fetching endpoint
{0x91C+0x20*i} DIEPDMAB{i} (i=1..15) — Device IN Endpoint Buffer Address Register {i}
  fields as DIEPDMAB0
0xB00 DOEPCTL0 reset 0x8000 — Device Control OUT Endpoint 0 Control Register
  [31] EPENA — Endpoint Enable (EPEna)
    0=INACTIVE (No action); 1=ACTIVE (Enable Endpoint)
  [30] EPDIS ro — Endpoint Disable (EPDis)
    0=INACTIVE (No Endpoint disable)
  [27] SNAK wo — Set NAK (SNAK)
    0=NOSET (No action); 1=SET (Set NAK)
  [26] CNAK wo — Clear NAK (CNAK)
    0=NOCLEAR (No action); 1=CLEAR (Clear NAK)
  [21] STALL — STALL Handshake (Stall)
    0=INACTIVE (No Stall); 1=ACTIVE (Stall Handshake)
  [19:18] EPTYPE ro — Endpoint Type (EPType)
    0=ACTIVE (Endpoint Control 0)
  [17] NAKSTS ro — NAK Status (NAKSts)
    values as DIEPCTL0.NAKSTS
  [15] USBACTEP ro — USB Active Endpoint (USBActEP)
    1=ACTIVE (USB Active Endpoint 0)
  [1:0] MPS ro — Maximum Packet Size (MPS)
    0=BYTE64 (64 bytes); 1=BYTE32 (32 bytes); 2=BYTE16 (16 bytes); 3=BYTE8 (8 bytes)
0xB08 DOEPINT0 — Device OUT Endpoint 0 Interrupt Register
  [15] STUPPKTRCVD — Setup Packet Received
    0=NOT_RCVD (No Setup packet received); 1=RCVD (Setup packet received)
  [14] NYETINTRPT — NYET Interrupt (NYETIntrpt)
    0=INACTIVE (No NYET interrupt); 1=ACTIVE (NYET Interrupt)
  [13] NAKINTRPT — NAK Interrupt (NAKInterrupt)
    0=INACTIVE (No NAK interrupt); 1=ACTIVE (NAK Interrupt)
  [12] BBLEERR — NAK Interrupt (BbleErr)
    0=INACTIVE (No BbleErr interrupt); 1=ACTIVE (BbleErr interrupt)
  [11] PKTDRPSTS — Packet Drop Status (PktDrpSts)
    values as DIEPINT1.PKTDRPSTS
  [9] BNAINTR — BNA (Buffer Not Available) Interrupt (BNAIntr)
    0=INACTIVE (No BNA interrupt); 1=ACTIVE (BNA interrupt)
  [8] OUTPKTERR — OUT Packet Error (OutPktErr)
    0=INACTIVE (No OUT Packet Error); 1=ACTIVE (OUT Packet Error)
  [6] BACK2BACKSETUP — Back-to-Back SETUP Packets Received (Back2BackSETup)
    0=INACTIVE (No Back-to-Back SETUP Packets Received); 1=ACTIVE (Back-to-Back SETUP Packets Received)
  [5] STSPHSERCVD — Status Phase Received for Control Write (StsPhseRcvd)
    0=INACTIVE (No Status Phase Received for Control Write); 1=ACTIVE (Status Phase Received for Control Write)
  [4] OUTTKNEPDIS — OUT Token Received When Endpoint Disabled (OUTTknEPdis)
    0=INACTIVE (No OUT Token Received When Endpoint Disabled); 1=ACTIVE (OUT Token Received When Endpoint Disabled)
  [3] SETUP — SETUP Phase Done (SetUp)
    0=INACTIVE (No SETUP Phase Done); 1=ACTIVE (SETUP Phase Done)
  [2] AHBERR — AHB Error (AHBErr)
    values as DIEPINT0.AHBERR
  [1] EPDISBLD — Endpoint Disabled Interrupt (EPDisbld)
    values as DIEPINT0.EPDISBLD
  [0] XFERCOMPL — Transfer Completed Interrupt (XferCompl)
    values as DIEPINT1.XFERCOMPL
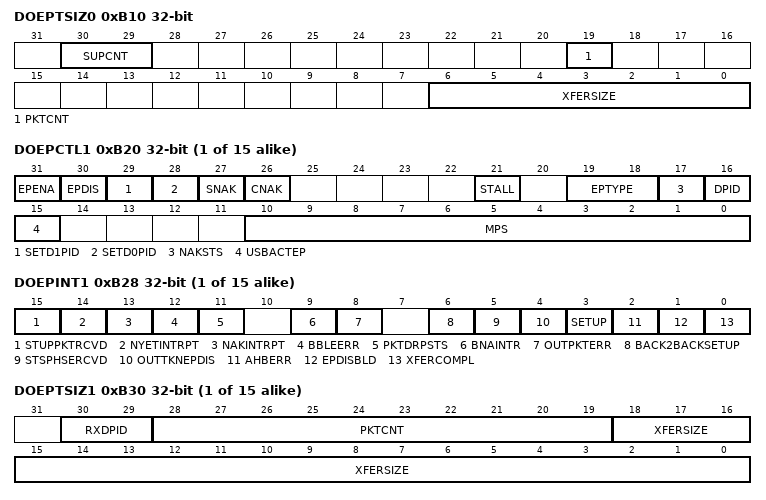
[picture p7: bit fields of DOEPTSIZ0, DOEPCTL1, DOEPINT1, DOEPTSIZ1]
0xB10 DOEPTSIZ0 — Device OUT Endpoint 0 Transfer Size Register
  [30:29] SUPCNT — SETUP Packet Count (SUPCnt)
    1=ONEPACKET (1 packet); 2=TWOPACKET (2 packets); 3=THREEPACKET (3 packets)
  [19] PKTCNT — Packet Count (PktCnt)
  [6:0] XFERSIZE — Transfer Size (XferSize)
0xB14 DOEPDMA0 — Device OUT Endpoint 0 DMA Address Register
  fields as DIEPDMA1
0xB1C DOEPDMAB0 — Device OUT Endpoint 0 DMA Buffer Address Register
  [31:0] DMABUFFERADDR ro
{0xB00+0x20*i} DOEPCTL{i} (i=1..15) — Device Control OUT Endpoint Control Register {i}
  [31] EPENA — Endpoint Enable (EPEna)
    0=INACTIVE (No Action); 1=ACTIVE (Enable Endpoint)
  [30] EPDIS — Endpoint Disable (EPDis)
    0=INACTIVE (No Action); 1=ACTIVE (Disable Endpoint)
  [29] SETD1PID wo — Set DATA1 PID (SetD1PID)
    0=DISABLED (Disables Set DATA1 PID or Do not force Odd Frame); 1=ENABLED (Set Endpoint Data PID to DATA1 or Sets EO_FrNum field to odd (micro)Frame)
  [28] SETD0PID wo — Set DATA0 PID (SetD0PID)
    0=DISABLED (Disables Set DATA0 PID or Do not force Even Frame); 1=ENABLED (Set Endpoint Data PID to DATA0 or Sets EO_FrNum field to odd (micro)Frame)
  [27] SNAK wo — Set NAK (SNAK)
    0=INACTIVE (No Set NAK); 1=ACTIVE (Set NAK)
  [26] CNAK wo
    0=INACTIVE (No Clear NAK); 1=ACTIVE (Clear NAK)
  [21] STALL — STALL Handshake (Stall)
    values as DIEPCTL1.STALL
  [19:18] EPTYPE — Endpoint Type (EPType)
    0=CONTROL; 1=ISOCHRONOUS; 2=BULK; 3=INTERRUPT
  [17] NAKSTS ro — NAK Status (NAKSts)
    values as DIEPCTL1.NAKSTS
  [16] DPID ro — Endpoint Data PID (DPID)
    0=INACTIVE (Endpoint Data PID not active); 1=ACTIVE (Endpoint Data PID active)
  [15] USBACTEP — USB Active Endpoint (USBActEP)
    0=DISABLED (Not Active); 1=ENABLED (USB Active Endpoint)
  [10:0] MPS — Maximum Packet Size (MPS)
{0xB08+0x20*i} DOEPINT{i} (i=1..15) — Device OUT Endpoint Interrupt Register {i}
  fields as DOEPINT0
{0xB10+0x20*i} DOEPTSIZ{i} (i=1..15) — Device OUT Endpoint Transfer Size Register {i}
  [30:29] RXDPID ro
    0=DATA0; 1=DATA2PACKET1 (DATA2 or 1 packet); 2=DATA1PACKET2 (DATA1 or 2 packets); 3=MDATAPACKET3 (MDATA or 3 packets)
  [28:19] PKTCNT — Packet Count (PktCnt)
  [18:0] XFERSIZE — Transfer Size (XferSize)
{0xB14+0x20*i} DOEPDMA{i} (i=1..15) — Device OUT Endpoint DMA Address Register {i}
  fields as DIEPDMA1
{0xB1C+0x20*i} DOEPDMAB{i} (i=1..15) — Device OUT Endpoint Buffer Address Register {i}
  fields as DIEPDMAB0
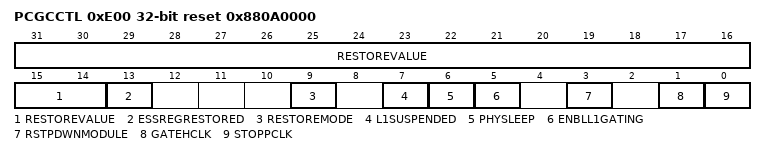
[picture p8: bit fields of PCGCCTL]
0xE00 PCGCCTL reset 0x880A0000 — Power and Clock Gating Control Register
  [31:14] RESTOREVALUE — Restore Value (RestoreValue)
  [13] ESSREGRESTORED wo — Essential Register Values Restored (EssRegRestored)
    0=NOT_RESTORED (Register values of essential registers are not restored); 1=RESTORED (Register values of essential registers have been restored)
  [9] RESTOREMODE — Restore Mode (RestoreMode)
    0=DISABLED (In Host mode,this bit indicates Host-initiated Resume and Reset. In Device mode, this bit indicates Device-initiated Remote Wakeup); 1=ENABLED (In Host mode,this bit indicates Device-initiated Remote Wakeup. In Device mode, this bit indicates Host-initiated Resume and Reset)
  [7] L1SUSPENDED ro — L1 Deep Sleep
    0=INACTIVE (Non Deep Sleep); 1=ACTIVE (Deep Sleep)
  [6] PHYSLEEP ro — PHY In Sleep
    0=INACTIVE (Phy not in Sleep state); 1=ACTIVE (Phy in Sleep state)
  [5] ENBLL1GATING — Enable Sleep Clock Gating
    0=DISABLED (The PHY clock is not gated in Sleep state); 1=ENABLED (The Core internal clock gating is enabled in Sleep state)
  [3] RSTPDWNMODULE — Reset Power-Down Modules (RstPdwnModule)
    0=ON (Power is turned on); 1=OFF (Power is turned off)
  [1] GATEHCLK — Gate Hclk (GateHclk)
    0=DISABLED (Clears this bit when the USB is resumed or a new session starts); 1=ENABLED (Sets this bit to gate hclk to modules when the USB is suspended or the session is not valid)
  [0] STOPPCLK — Stop Pclk (StopPclk)
    0=DISABLED (Disable Stop Pclk); 1=ENABLED (Enable Stop Pclk)
{0x1000+0x1000*i} DWCOTGDFIFO[{i}] (i=0..15) group — Unspecified
  {0x0+4j} DATA[{j}] (j=0..1023) — Description collection: Data FIFO Access Register Map 0
0x11000 DWCOTGDFIFODIRECTACCESS group — Unspecified
  {0x0+4j} DATA[{j}] (j=0..32767) — Description collection: Data FIFO Direct Access Register Map
